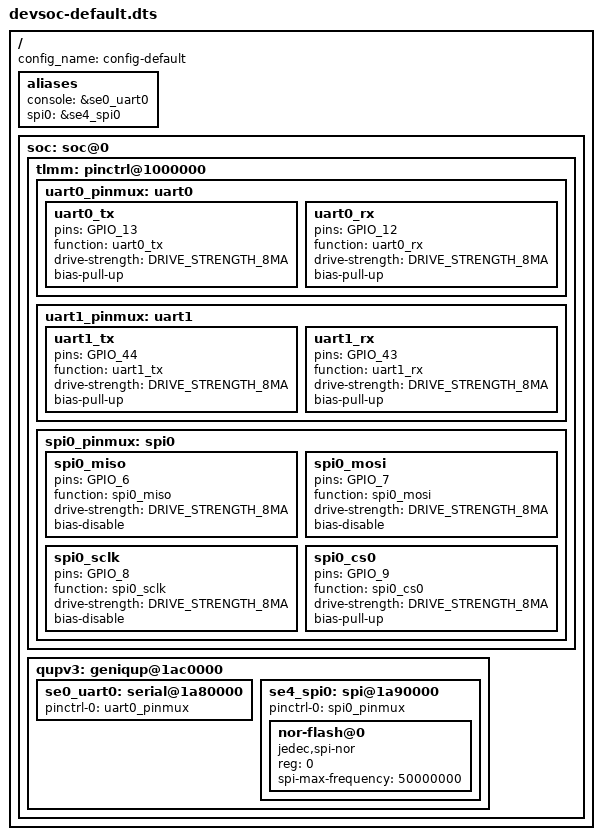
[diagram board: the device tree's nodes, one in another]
// SPDX-License-Identifier: GPL-2.0-only
/*
* Copyright (c) 2023, Qualcomm Innovation Center, Inc. All rights reserved.
*/

#include "devsoc.dtsi"

/ {
	config_name = "config-default";

	aliases {
		console = &se0_uart0;
		spi0 = &se4_spi0;
	};

	soc: soc@0 {
		tlmm: pinctrl@1000000 {
			uart0_pinmux: uart0 {
				uart0_tx {
					pins = "GPIO_13";
					function = "uart0_tx";
					drive-strength = <DRIVE_STRENGTH_8MA>;
					bias-pull-up;
				};

				uart0_rx {
					pins = "GPIO_12";
					function = "uart0_rx";
					drive-strength = <DRIVE_STRENGTH_8MA>;
					bias-pull-up;
				};
			};

			uart1_pinmux: uart1 {
				uart1_tx {
					pins = "GPIO_44";
					function = "uart1_tx";
					drive-strength = <DRIVE_STRENGTH_8MA>;
					bias-pull-up;
				};

				uart1_rx {
					pins = "GPIO_43";
					function = "uart1_rx";
					drive-strength = <DRIVE_STRENGTH_8MA>;
					bias-pull-up;
				};
			};

			spi0_pinmux: spi0 {
				spi0_miso {
					pins = "GPIO_6";
					function = "spi0_miso";
					drive-strength = <DRIVE_STRENGTH_8MA>;
					bias-disable;
				};

				spi0_mosi {
					pins = "GPIO_7";
					function = "spi0_mosi";
					drive-strength = <DRIVE_STRENGTH_8MA>;
					bias-disable;
				};

				spi0_sclk {
					pins = "GPIO_8";
					function = "spi0_sclk";
					drive-strength = <DRIVE_STRENGTH_8MA>;
					bias-disable;
				};

				spi0_cs0 {
					pins = "GPIO_9";
					function = "spi0_cs0";
					drive-strength = <DRIVE_STRENGTH_8MA>;
					bias-pull-up;
				};
			};
		};

		qupv3: geniqup@1ac0000 {
			status = "okay";

			se0_uart0: serial@1a80000 {
				pinctrl-0 = <&uart0_pinmux>;
				pinctrl-names = "default";
				status = "okay";
			};

			se4_spi0: spi@1a90000 {
				pinctrl-0 = <&spi0_pinmux>;
				pinctrl-names = "default";
				status = "okay";

				nor-flash@0 {
					compatible = "jedec,spi-nor";
					reg = <0>;
					spi-max-frequency = <50000000>;
				};
			};
		};
	};
};
